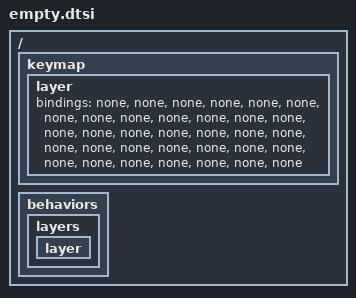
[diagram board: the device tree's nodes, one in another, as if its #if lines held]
// Copyright (c) 2022 The ZMK Contributors
// SPDX-License-Identifier: MIT

#define B_LAYER(key) B_LAYER(layer, key)

/ {
    keymap {
        layer {
            bindings = <
        // ╭──────────────┬──────────────┬──────────────┬──────────────┬──────────────╮   ╭──────────────┬──────────────┬──────────────┬──────────────┬──────────────╮
        // │              │              │              │              │              │   │              │              │              │              │              │
             &none          &none          &none          &none          &none              &none          &none          &none          &none          &none
        // ├──────────────┼──────────────┼──────────────┼──────────────┼──────────────┤   ├──────────────┼──────────────┼──────────────┼──────────────┼──────────────┤
        // │              │              │              │              │              │   │              │              │              │              │              │
             &none          &none          &none          &none          &none              &none          &none          &none          &none          &none
        // ├──────────────┼──────────────┼──────────────┼──────────────┼──────────────┤   ├──────────────┼──────────────┼──────────────┼──────────────┼──────────────┤
        // │              │              │              │              │              │   │              │              │              │              │              │
             &none          &none          &none          &none          &none              &none          &none          &none          &none          &none
        // ╰──────────────┴──────────────┴──────────────┼──────────────┼──────────────┤   ├──────────────┼──────────────┼──────────────┴──────────────┴──────────────╯
#ifdef KEY_34
        //                                              ╭──────────────┬──────────────╮   ╭──────────────┬──────────────╮
        //                                              |              |              |   |              |              |
                                                          &none          &none              &none          &none
        //                                              ╰──────────────┴──────────────╯   ╰──────────────┴──────────────╯
#else
        //                               ╭──────────────┬──────────────┬──────────────╮   ╭──────────────┬──────────────┬──────────────╮
        //                               |              |              |              |   |              |              |              |
                                           &none          &none          &none              &none          &none          &none
        //                               ╰──────────────┴──────────────┴──────────────╯   ╰──────────────┴──────────────┴──────────────╯
#endif
            >;
        };
    };

    behaviors {
        layers {
            layer {
            };
        };
    };
};
